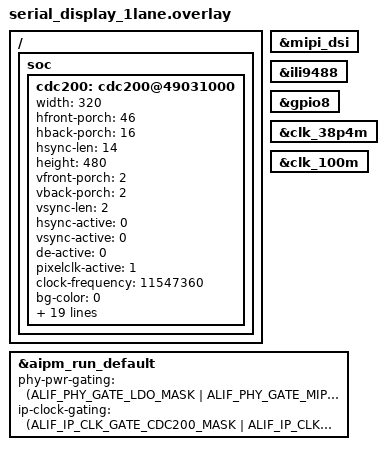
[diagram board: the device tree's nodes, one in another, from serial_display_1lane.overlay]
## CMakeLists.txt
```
# Copyright (C) 2026 Alif Semiconductor - All Rights Reserved.
# Use, distribution and modification of this code is permitted under the
# terms stated in the Alif Semiconductor Software License Agreement
#
# You should have received a copy of the Alif Semiconductor Software
# License Agreement with this file. If not, please write to:
# contact@alifsemi.com, or visit: https://alifsemi.com/license


cmake_minimum_required(VERSION 3.20.0)
find_package(Zephyr REQUIRED HINTS $ENV{ZEPHYR_BASE})
project(disp_pm)

target_sources(app PRIVATE src/main.c src/display_pm_test.c)
target_include_directories(app PRIVATE src)
```

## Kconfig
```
# Copyright (C) 2026 Alif Semiconductor - All Rights Reserved.
# Use, distribution and modification of this code is permitted under the
# terms stated in the Alif Semiconductor Software License Agreement
#
# You should have received a copy of the Alif Semiconductor Software
# License Agreement with this file. If not, please write to:
# contact@alifsemi.com, or visit: https://alifsemi.com/license


mainmenu "Alif Display Power Management Demo"

source "Kconfig.zephyr"
```

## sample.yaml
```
sample:
  name: Alif Display Power Management Demo
  description: >
    Demonstrates Zephyr power management states (PM_STATE_RUNTIME_IDLE,
    PM_STATE_SUSPEND_TO_IDLE, PM_STATE_SUSPEND_TO_RAM, PM_STATE_SOFT_OFF)
    for Alif RTSS cores with Display between PM state transitions.
    PM states exercised are selected via build snippets: display-pm-s2ram-tcm
    (HE TCM retention), display-pm-mram (MRAM boot SOFT_OFF, HE or HP).
common:
  tags:
    - power
    - pm
    - display
    - counter
    - rtc
    - drivers
  filter: SOC_FAMILY_ENSEMBLE
  harness: console
  harness_config:
    type: multi_line
    regex:
      - "DISPLAY PM demo"
      - "POWER STATE SEQUENCE"
tests:
  sample.drivers.display.pm.s2ram_tcm:
    platform_allow:
      - alif_e7_dk_rtss_he
      - alif_e8_dk_rtss_he
      - alif_e1c_dk_rtss_he
      - alif_b1_dk_rtss_he
    integration_platforms:
      - alif_e7_dk_rtss_he
    depends_on:
      - counter
    extra_args:
      - SNIPPET=display-pm-s2ram-tcm
  sample.drivers.display.pm.mram:
    platform_allow:
      - alif_e7_dk_rtss_he
      - alif_e7_dk_rtss_hp
      - alif_e8_dk_rtss_he
      - alif_e8_dk_rtss_hp
      - alif_e1c_dk_rtss_he
      - alif_b1_dk_rtss_he
    integration_platforms:
      - alif_e7_dk_rtss_he
      - alif_e7_dk_rtss_hp
    depends_on:
      - counter
    extra_args:
      - SNIPPET=display-pm-mram
```

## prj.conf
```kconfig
CONFIG_PM=y
CONFIG_PM_DEVICE=y
CONFIG_POWER_DOMAIN=y
CONFIG_IDLE_STACK_SIZE=1024
CONFIG_SYS_CLOCK_TICKS_PER_SEC=1000

CONFIG_COUNTER=y

CONFIG_STDOUT_CONSOLE=y
CONFIG_PRINTK=y
CONFIG_ASSERT=y

CONFIG_LOG=y
CONFIG_LOG_DEFAULT_LEVEL=0
CONFIG_LOG_MODE_DEFERRED=y
CONFIG_LOG_PROCESS_THREAD_SLEEP_MS=5
CONFIG_PM_DEVICE_LOG_LEVEL_WRN=y

# Display
CONFIG_DISPLAY=y
```

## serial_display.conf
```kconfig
# Copyright (C) 2026 Alif Semiconductor - All Rights Reserved.
# Use, distribution and modification of this code is permitted under the
# terms stated in the Alif Semiconductor Software License Agreement
#
# You should have received a copy of the Alif Semiconductor Software
# License Agreement with this file. If not, please write to:
# contact@alifsemi.com, or visit: https://alifsemi.com/license

CONFIG_MIPI_DSI=y
```

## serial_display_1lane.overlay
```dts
/* Copyright (C) Alif Semiconductor - All Rights Reserved.
 * Use, distribution and modification of this code is permitted under the
 * terms stated in the Alif Semiconductor Software License Agreement
 *
 * You should have received a copy of the Alif Semiconductor Software
 * License Agreement with this file. If not, please write to:
 * contact@alifsemi.com, or visit: https://alifsemi.com/license
 *
 */

#include <dt-bindings/misc/alif_aipm_common.h>

/ {
	soc {
		cdc200: cdc200@49031000 {
			width = <320>;
			hfront-porch = <46>;
			hback-porch = <16>;
			hsync-len = <14>;

			height = <480>;
			vfront-porch = <2>;
			vback-porch = <2>;
			vsync-len = <2>;

			hsync-active = <0>;
			vsync-active = <0>;
			de-active = <0>;
			pixelclk-active = <1>;

			clock-frequency = <11547360>;

			bg-color = <0>;
			enable-l1 = <1>;
			pixel-fmt-l1 = "rgb-565";
			def-back-color-l1 = <0>;
			win-x0-l1 = <0>;
			win-y0-l1 = <0>;
			win-x1-l1 = <320>;
			win-y1-l1 = <480>;
			blend-factor1-l1 = <4>;
			blend-factor2-l1 = <5>;
			const-alpha-l1 = <0xff>;
			enable-l2 = <0>;
			pixel-fmt-l2 = "undefined";
			win-x0-l2 = <0>;
			win-y0-l2 = <0>;
			win-x1-l2 = <0>;
			win-y1-l2 = <0>;
			blend-factor1-l2 = <6>;
			blend-factor2-l2 = <7>;
			const-alpha-l2 = <0xff>;
		};
	};
};

&mipi_dsi {
	status = "okay";
};

&ili9488 {
	status = "okay";
};

&gpio8 {
	status = "okay";
};

/* enable HFOSC clock clk_38p4m. */
&clk_38p4m {
	status = "okay";
};

/* enable CFG clock clk_100m. */
&clk_100m {
	status = "okay";
};

&aipm_run_default {
	phy-pwr-gating = <(ALIF_PHY_GATE_LDO_MASK |
			ALIF_PHY_GATE_MIPI_TX_DPHY_MASK |
			ALIF_PHY_GATE_MIPI_RX_DPHY_MASK |
			ALIF_PHY_GATE_MIPI_PLL_DPHY_MASK)>;
	ip-clock-gating = <(ALIF_IP_CLK_GATE_CDC200_MASK |
			ALIF_IP_CLK_GATE_MIPI_DSI_MASK |
			ALIF_IP_CLK_GATE_GPU_MASK)>;
};
```

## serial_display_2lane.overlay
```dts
/* Copyright (C) 2026 Alif Semiconductor - All Rights Reserved.
 * Use, distribution and modification of this code is permitted under the
 * terms stated in the Alif Semiconductor Software License Agreement
 *
 * You should have received a copy of the Alif Semiconductor Software
 * License Agreement with this file. If not, please write to:
 * contact@alifsemi.com, or visit: https://alifsemi.com/license
 *
 */

/ {
	soc {
		cdc200: cdc200@49031000 {
			width = <480>;
			height = <800>;
			hfront-porch = <5>;
			hback-porch = <5>;
			hsync-len = <4>;
			vfront-porch = <10>;
			vback-porch = <10>;
			vsync-len = <2>;
			clock-frequency = <24364080>;
			hsync-active = <0>;
			vsync-active = <0>;
			de-active = <1>;
			pixelclk-active = <0>;
			bg-color = <0>;
			enable-l1 = <1>;
			pixel-fmt-l1 = "rgb-888";
			def-back-color-l1 = <0>;
			win-x0-l1 = <0>;
			win-y0-l1 = <0>;
			win-x1-l1 = <480>;
			win-y1-l1 = <800>;
			blend-factor1-l1 = <4>;
			blend-factor2-l1 = <5>;
			const-alpha-l1 = <0xff>;
			enable-l2 = <0>;
			pixel-fmt-l2 = "undefined";
			win-x0-l2 = <0>;
			win-y0-l2 = <0>;
			win-x1-l2 = <0>;
			win-y1-l2 = <0>;
			blend-factor1-l2 = <6>;
			blend-factor2-l2 = <7>;
			const-alpha-l2 = <0xff>;
		};
	};
};

&mipi_dsi {
	status = "okay";
};

/* enable HFOSC clock clk_38p4m. */
&clk_38p4m {
	status = "okay";
};

/* enable CFG clock clk_100m. */
&clk_100m {
	status = "okay";
};

&aipm_run_default {
	phy-pwr-gating = <(ALIF_PHY_GATE_LDO_MASK |
			ALIF_PHY_GATE_MIPI_TX_DPHY_MASK |
			ALIF_PHY_GATE_MIPI_RX_DPHY_MASK |
			ALIF_PHY_GATE_MIPI_PLL_DPHY_MASK)>;
	ip-clock-gating = <(ALIF_IP_CLK_GATE_CDC200_MASK |
			ALIF_IP_CLK_GATE_MIPI_DSI_MASK |
			ALIF_IP_CLK_GATE_GPU_MASK)>;
};
```

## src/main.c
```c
/* Copyright (C) 2026 Alif Semiconductor - All Rights Reserved.
 * Use, distribution and modification of this code is permitted under the
 * terms stated in the Alif Semiconductor Software License Agreement
 *
 * You should have received a copy of the Alif Semiconductor Software
 * License Agreement with this file. If not, please write to:
 * contact@alifsemi.com, or visit: https://alifsemi.com/license
 *
 */

#include "aipm.h"
#include <stdio.h>
#include <zephyr/kernel.h>
#include <zephyr/device.h>
#include <zephyr/init.h>
#include <zephyr/pm/pm.h>
#include <zephyr/pm/policy.h>
#if defined(CONFIG_POWEROFF)
#include <zephyr/sys/poweroff.h>
#endif
#include <zephyr/drivers/counter.h>
#include <se_service.h>
#include <soc_common.h>
#include <zephyr/sys/util.h>
#include <zephyr/logging/log.h>
#include "display_pm_test.h"
#include <zephyr/drivers/clock_control.h>
#include <zephyr/dt-bindings/clock/alif_ensemble_clocks.h>
#include <zephyr/drivers/gpio.h>

LOG_MODULE_REGISTER(disp_pm, LOG_LEVEL_DBG);

/* Set to 1 to dump full NVIC ISPR state on wakeup */
#define APP_PM_WAKEUP_DEBUG 0

#if DT_NODE_HAS_COMPAT_STATUS(DT_NODELABEL(rtc0), snps_dw_apb_rtc, okay)
	#define WAKEUP_SOURCE DT_NODELABEL(rtc0)
#elif DT_NODE_HAS_COMPAT_STATUS(DT_NODELABEL(timer0), snps_dw_timers, okay)
	#define WAKEUP_SOURCE DT_NODELABEL(timer0)
#else
#error "Wakeup Device not enabled in the dts"
#endif

/*
 * Sleep duration constants for each PM state.
 *
 * Upper bound: at 400 MHz, ticks to cycles calculation in PM driver
 * overflows uint32 max for values > 10.7s (2^32 / 400). All deep-sleep
 * durations and overlay min-residency-us values must stay below this ceiling.
 */
/* Sleep duration for PM_STATE_RUNTIME_IDLE */
#define RUNTIME_IDLE_SLEEP_USEC (10 * 1000 * 1000)
/* Sleep duration for PM_STATE_SUSPEND_TO_IDLE */
#define SUSPEND_IDLE_SLEEP_USEC (10 * 1000)
/* Sleep duration for PM_STATE_SUSPEND_TO_RAM substate 0 (STANDBY) */
#define S2RAM_STANDBY_SLEEP_USEC (6 * 1000 * 1000)
/* Sleep duration for PM_STATE_SUSPEND_TO_RAM substate 1 (STOP) */
#define S2RAM_STOP_SLEEP_USEC (9 * 1000 * 1000)
/* Sleep duration for PM_STATE_SOFT_OFF */
#define SOFT_OFF_SLEEP_USEC (10 * 1000 * 1000)

/*
 * MRAM base address - used to determine boot location
 * TCM boot: VTOR = 0x0
 * MRAM boot: VTOR >= 0x80000000
 */
#define MRAM_BASE_ADDRESS 0x80000000

/*
 * Helper macro to check if booting from MRAM
 */
#define IS_BOOTING_FROM_MRAM() (SCB->VTOR >= MRAM_BASE_ADDRESS)

/*
 * True when the DTS chosen zephyr,sram points at sram0. The snippet overlay
 * is responsible for ensuring SRAM0 has retention support on the target board.
 */
#if DT_NODE_EXISTS(DT_NODELABEL(sram0))
#define IS_SRAM0_CONFIGURED_AS_RAM() \
	DT_SAME_NODE(DT_CHOSEN(zephyr_sram), DT_NODELABEL(sram0))
#else
#define IS_SRAM0_CONFIGURED_AS_RAM() 0
#endif

/*
 * S2RAM_SUPPORTED — retention-capable sleep is possible when:
 *   - SRAM0 is the configured data RAM (HE or HP, E8 only), OR
 *   - HE core booting from TCM (TCM has hardware retention)
 *
 * SOFT_OFF_SUPPORTED — mutually exclusive with S2RAM: used when no
 * retained RAM is available (HP-TCM, HE-MRAM boot without SRAM0).
 */
#define S2RAM_SUPPORTED \
	(IS_SRAM0_CONFIGURED_AS_RAM() || \
	 (IS_ENABLED(CONFIG_RTSS_HE) && !IS_BOOTING_FROM_MRAM()))

#define SOFT_OFF_SUPPORTED (!S2RAM_SUPPORTED)

/* Validate ordering of deep-sleep durations at compile time */
BUILD_ASSERT((S2RAM_STOP_SLEEP_USEC > S2RAM_STANDBY_SLEEP_USEC),
	"STOP sleep duration should be greater than STANDBY sleep duration");
BUILD_ASSERT((SOFT_OFF_SLEEP_USEC > S2RAM_STOP_SLEEP_USEC),
	"SOFT_OFF sleep duration should be greater than STOP sleep duration");

/**
 * Helper function to lock/unlock deeper power states.
 * @param lock true → lock all deep states (allow RUNTIME_IDLE only)
 *             false → unlock the applicable state; keep the other locked
 */
static void app_pm_lock_deeper_states(bool lock)
{
	if (lock) {
		pm_policy_state_lock_get(PM_STATE_SUSPEND_TO_RAM, PM_ALL_SUBSTATES);
		pm_policy_state_lock_get(PM_STATE_SOFT_OFF,       PM_ALL_SUBSTATES);
	} else {
		pm_policy_state_lock_put(PM_STATE_SOFT_OFF,       PM_ALL_SUBSTATES);
		pm_policy_state_lock_put(PM_STATE_SUSPEND_TO_RAM, PM_ALL_SUBSTATES);
	}
}

/*
 * Lock every PM sleep state deeper than RUNTIME_IDLE. Intended for use around
 * peripheral transfers (see spi_loopback_run()) and around any sleep call the
 * app makes where an accidental upgrade to a deeper state must be prevented.
 */
static void app_pm_lock_sleep_states(bool lock)
{
	if (lock) {
		pm_policy_state_lock_get(PM_STATE_SUSPEND_TO_IDLE, PM_ALL_SUBSTATES);
		pm_policy_state_lock_get(PM_STATE_SUSPEND_TO_RAM,  PM_ALL_SUBSTATES);
		pm_policy_state_lock_get(PM_STATE_SOFT_OFF,        PM_ALL_SUBSTATES);
	} else {
		pm_policy_state_lock_put(PM_STATE_SOFT_OFF,        PM_ALL_SUBSTATES);
		pm_policy_state_lock_put(PM_STATE_SUSPEND_TO_RAM,  PM_ALL_SUBSTATES);
		pm_policy_state_lock_put(PM_STATE_SUSPEND_TO_IDLE, PM_ALL_SUBSTATES);
	}
}

#if !defined(CONFIG_CORTEX_M_SYSTICK_LPM_TIMER_COUNTER)
static volatile uint32_t alarm_cb_status;
static void alarm_callback_fn(const struct device *wakeup_dev,
				uint8_t chan_id, uint32_t ticks,
				void *user_data)
{
	LOG_DBG("%s: Alarm triggered", wakeup_dev->name);
	alarm_cb_status = 1;
}
#endif

static int app_enter_normal_sleep(uint32_t sleep_usec)
{
	int ret;

	ret = display_pm_thread_suspend();
	if (ret) {
		LOG_ERR("Failed to suspend display thread: %d", ret);
		return ret;
	}
	LOG_INF("Display streaming is Suspended: for normal sleep");

#if defined(CONFIG_CORTEX_M_SYSTICK_LPM_TIMER_COUNTER)
	k_sleep(K_USEC(sleep_usec));
#else
	const struct device *const wakeup_dev = DEVICE_DT_GET(WAKEUP_SOURCE);
	struct counter_alarm_cfg alarm_cfg;

	alarm_cfg.flags = 0;
	alarm_cfg.ticks = counter_us_to_ticks(wakeup_dev, sleep_usec);
	alarm_cfg.callback = alarm_callback_fn;
	alarm_cfg.user_data = &alarm_cfg;

	ret = counter_set_channel_alarm(wakeup_dev, 0, &alarm_cfg);
	if (ret) {
		LOG_ERR("Could not set the alarm");
		display_pm_thread_resume();
		return ret;
	}
	LOG_DBG("Set alarm for %u microseconds", sleep_usec);

	k_sleep(K_USEC(sleep_usec));

	if (!alarm_cb_status) {
		display_pm_thread_resume();
		return -1;
	}
	alarm_cb_status = 0;

#endif
	return 0;
}

static int app_enter_deep_sleep(uint32_t sleep_usec)
{
	int ret;

	ret = display_pm_thread_suspend();
	if (ret) {
		LOG_ERR("Failed to suspend display thread: %d", ret);
		return ret;
	}
	LOG_INF("Display streaming is Suspended: for Deep Sleep");

#if defined(CONFIG_CORTEX_M_SYSTICK_LPM_TIMER_COUNTER)
	/**
	 * Set a delay more than the min-residency-us configured so that
	 * the sub-system will go to OFF state.
	 */
	k_sleep(K_USEC(sleep_usec));
#else
	const struct device *const wakeup_dev = DEVICE_DT_GET(WAKEUP_SOURCE);
	struct counter_alarm_cfg alarm_cfg = {0};
	/*
	 * Set the alarm and delay so that idle thread can run
	 */
	alarm_cfg.ticks = counter_us_to_ticks(wakeup_dev, sleep_usec);
	alarm_cfg.callback = alarm_callback_fn;
	ret = counter_set_channel_alarm(wakeup_dev, 0, &alarm_cfg);
	if (ret) {
		LOG_ERR("Failed to set the alarm (err %d)", ret);
		display_pm_thread_resume();
		return ret;
	}

	LOG_DBG("Set alarm for %u microseconds", sleep_usec);
	/*
	 * Wait for the alarm to trigger. The idle thread will
	 * take care of entering the deep sleep state via PM framework.
	 */
	k_sleep(K_USEC(sleep_usec));
#endif

	ret = display_pm_thread_resume();
	if (ret) {
		LOG_ERR("Failed to resume display thread: %d", ret);
		return ret;
	}
	LOG_INF("Display stream is Resumed: for Deep Sleep");

	return 0;
}

/* PM state name lookup for notifier logging */
static const char * const pm_state_names[] = {
	[PM_STATE_ACTIVE]          = "ACTIVE",
	[PM_STATE_RUNTIME_IDLE]    = "RUNTIME_IDLE",
	[PM_STATE_SUSPEND_TO_IDLE] = "SUSPEND_TO_IDLE",
	[PM_STATE_STANDBY]         = "STANDBY",
	[PM_STATE_SUSPEND_TO_RAM]  = "SUSPEND_TO_RAM",
	[PM_STATE_SUSPEND_TO_DISK] = "SUSPEND_TO_DISK",
	[PM_STATE_SOFT_OFF]        = "SOFT_OFF",
};

#define PM_STATE_STR(s) \
	((s) < ARRAY_SIZE(pm_state_names) ? pm_state_names[(s)] : "UNKNOWN")

static void pm_notify_entry(enum pm_state state)
{
	const struct pm_state_info *info = pm_state_next_get(0);

	LOG_INF("PM enter: %s (substate %u)", PM_STATE_STR(state), info->substate_id);
}

/*
 * With CONFIG_LOG_MODE_DEFERRED, LOG_INF here only writes to the ring buffer
 * — no UART access — so this is safe even before devices are resumed.
 */
static void pm_notify_pre_resume(enum pm_state state)
{
	const struct pm_state_info *info = pm_state_next_get(0);
	uint32_t active_exc = SCB->ICSR & SCB_ICSR_VECTACTIVE_Msk;

	if (active_exc >= 16U) {
		LOG_INF("PM wakeup: %s (substate %u) IRQ %u",
			PM_STATE_STR(state), info->substate_id, active_exc - 16U);
	} else if (active_exc != 0U) {
		LOG_INF("PM wakeup: %s (substate %u) exception %u",
			PM_STATE_STR(state), info->substate_id, active_exc);
	} else {
		LOG_INF("PM wakeup: %s (substate %u)",
			PM_STATE_STR(state), info->substate_id);
	}
#if APP_PM_WAKEUP_DEBUG
	for (int i = 0; i < 16; i++) {
		if (NVIC->ISPR[i]) {
			LOG_INF("PM wakeup: NVIC ISPR[%d] = 0x%08x", i, NVIC->ISPR[i]);
		}
	}
#endif

	if (info->substate_id == 1) {
#if (defined(CONFIG_ENSEMBLE_GEN2) && defined(CONFIG_MIPI_DSI))
		const struct gpio_dt_spec cam_disp_mux_gpio =
			GPIO_DT_SPEC_GET(DT_NODELABEL(mipi_dsi), cam_disp_mux_gpios);
		gpio_pin_configure_dt(&cam_disp_mux_gpio, GPIO_OUTPUT_ACTIVE);
#endif
	}
}

static void pm_notify_exit(enum pm_state state)
{
	const struct pm_state_info *info = pm_state_next_get(0);

	LOG_INF("PM exit:  %s (substate %u)", PM_STATE_STR(state), info->substate_id);
}

static struct pm_notifier app_pm_notifier = {
	.state_entry       = pm_notify_entry,
	.pre_device_resume = pm_notify_pre_resume,
	.state_exit        = pm_notify_exit,
};

int main(void)
{
	const struct device *const cons = DEVICE_DT_GET(DT_CHOSEN(zephyr_console));
	const struct device *const wakeup_dev = DEVICE_DT_GET(WAKEUP_SOURCE);
	int ret;

	__ASSERT(device_is_ready(cons), "%s: device not ready", cons->name);
	__ASSERT(device_is_ready(wakeup_dev), "%s: device not ready", wakeup_dev->name);

	pm_notifier_register(&app_pm_notifier);

	if (S2RAM_SUPPORTED) {
		LOG_INF("%s (S2RAM): Display PM demo "
			"(RUNTIME_IDLE, SUSPEND_TO_IDLE, S2RAM STANDBY, S2RAM STOP)",
			CONFIG_BOARD);
	} else {
		LOG_INF("%s (SOFT_OFF): Display PM demo "
			"(RUNTIME_IDLE, SUSPEND_TO_IDLE, SOFT_OFF)",
			CONFIG_BOARD);
	}

	display_pm_thread_init();
	display_pm_thread_start();

	ret = counter_start(wakeup_dev);
	__ASSERT(!ret || ret == -EALREADY, "Failed to start counter (err %d)", ret);

	LOG_INF("POWER STATE SEQUENCE:");
	/* HE core: sequence depends on boot location */
	LOG_INF("  1. PM_STATE_RUNTIME_IDLE");
	LOG_INF("  2. PM_STATE_SUSPEND_TO_IDLE");
	if (S2RAM_SUPPORTED) {
		/* TCM boot: S2RAM works (TCM retention) */
		LOG_INF("  3. PM_STATE_SUSPEND_TO_RAM (substate 0: STANDBY)");
		LOG_INF("  4. PM_STATE_SUSPEND_TO_RAM (substate 1: STOP)");
	} else {
		/* MRAM boot: Enable Only SOFT_OFF */
		LOG_INF("  3. PM_STATE_SOFT_OFF");
	}

	LOG_INF("Enter RUNTIME_IDLE sleep for (%d microseconds)", RUNTIME_IDLE_SLEEP_USEC);
	app_pm_lock_sleep_states(true);
	ret = app_enter_normal_sleep(RUNTIME_IDLE_SLEEP_USEC);
	app_pm_lock_sleep_states(false);
	__ASSERT(ret == 0, "Could not enter RUNTIME_IDLE sleep (err %d)", ret);

	LOG_INF("Exited from RUNTIME_IDLE sleep");

	display_pm_thread_resume();
	ret = display_pm_wait_streaming_done();
	__ASSERT(ret == 0, "Display stream did not complete successfully (err %d)", ret);
	LOG_INF("Display streaming cycle OK (RUNTIME_IDLE)");

#if defined(CONFIG_CORTEX_M_SYSTICK_LPM_TIMER_COUNTER)
	LOG_INF("Request SUSPEND_TO_IDLE for %d us", SUSPEND_IDLE_SLEEP_USEC);
	app_pm_lock_deeper_states(true);
	k_sleep(K_USEC(SUSPEND_IDLE_SLEEP_USEC));
	app_pm_lock_deeper_states(false);
	LOG_INF("Exited from SUSPEND_TO_IDLE sleep");
#else
	/* Lock SUSPEND_TO_IDLE when LPM timer support is not configured */
	pm_policy_state_lock_get(PM_STATE_SUSPEND_TO_IDLE, PM_ALL_SUBSTATES);
	LOG_INF("PM_STATE_SUSPEND_TO_IDLE (skipped - LPM timer not enabled)");
#endif

	if (S2RAM_SUPPORTED) {
		LOG_INF("Request S2RAM STANDBY for %d us", S2RAM_STANDBY_SLEEP_USEC);
		ret = app_enter_deep_sleep(S2RAM_STANDBY_SLEEP_USEC);
		__ASSERT(ret == 0, "Could not enter PM_STATE_SUSPEND_TO_RAM (err %d)", ret);

		LOG_INF("=== Resumed from PM_STATE_SUSPEND_TO_RAM (substate 0: STANDBY) ===");

		display_pm_wait_streaming_done();
		LOG_INF("Display streaming cycle OK (RUNTIME_IDLE)");

		/* Verify main thread is running properly */
		for (int i = 0; i < 3; i++) {
			LOG_INF("Main thread running - iteration %d - tick: %llu",
				i, k_uptime_ticks());
			k_sleep(K_SECONDS(2));
		}

		LOG_INF("Request S2RAM STOP for %d us", S2RAM_STOP_SLEEP_USEC);
		ret = app_enter_deep_sleep(S2RAM_STOP_SLEEP_USEC);
		__ASSERT(ret == 0, "Could not enter PM_STATE_SUSPEND_TO_RAM (err %d)", ret);

		LOG_INF("=== Resumed from PM_STATE_SUSPEND_TO_RAM (substate 1: STOP) ===");

		display_pm_wait_streaming_done();
		LOG_INF("Display streaming cycle OK (STOP)");

		/* Verify main thread is running properly */
		for (int i = 0; i < 3; i++) {
			LOG_INF("Main thread running - iteration %d - tick: %llu",
				i, k_uptime_ticks());
			k_sleep(K_SECONDS(2));
		}
	}

	/* HE core: only SOFT_OFF when booting from MRAM */
	if (SOFT_OFF_SUPPORTED) {
		LOG_INF("Request SOFT_OFF for %d us (no retention - system resets on wakeup)",
			SOFT_OFF_SLEEP_USEC);
		ret = app_enter_deep_sleep(SOFT_OFF_SLEEP_USEC);
		__ASSERT(ret == 0, "Could not enter PM_STATE_SOFT_OFF (err %d)", ret);

		/* Should never reach here - SOFT_OFF causes full reset on wakeup */
		LOG_ERR("ERROR: Resumed after PM_STATE_SOFT_OFF - this should not happen!");
		__ASSERT(false, "PM_STATE_SOFT_OFF should have caused a reset");
	}

	LOG_INF("=== DISPLAY PM SEQUENCE COMPLETED ===");

	display_pm_thread_stop();
	LOG_INF("Display Streaming is Stopped (PM sequence done)");

	app_pm_lock_deeper_states(true);
	/* Demo complete — prevent SUSPEND_TO_IDLE so the idle spin stays in RUNTIME_IDLE */
	pm_policy_state_lock_get(PM_STATE_SUSPEND_TO_IDLE, PM_ALL_SUBSTATES);

	while (true) {
		/* spin here */
		k_sleep(K_SECONDS(1));
	}

	return 0;
}
```

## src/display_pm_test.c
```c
/* Copyright (C) 2026 Alif Semiconductor - All Rights Reserved.
 * Use, distribution and modification of this code is permitted under the
 * terms stated in the Alif Semiconductor Software License Agreement
 *
 * You should have received a copy of the Alif Semiconductor Software
 * License Agreement with this file. If not, please write to:
 * contact@alifsemi.com, or visit: https://alifsemi.com/license
 *
 */

#include <zephyr/kernel.h>
#include <zephyr/device.h>
#include <zephyr/devicetree.h>
#include <string.h>
#include <zephyr/drivers/gpio.h>
#include <zephyr/drivers/display.h>
#include <zephyr/drivers/display/cdc200.h>
#include <soc_common.h>
#include <se_service.h>
#include <zephyr/pm/device.h>
#include <zephyr/pm/policy.h>
#include <zephyr/logging/log.h>
#ifdef CONFIG_MIPI_DSI
#include <zephyr/drivers/mipi_dsi/dsi_dw.h>
#endif /* CONFIG_MIPI_DSI */
#include <zephyr/cache.h>
#include "alif_logo.h"

#include "display_pm_test.h"

LOG_MODULE_DECLARE(disp_pm, LOG_LEVEL_DBG);

/* size of stack area used by each thread */
#define STACKSIZE 4096

/* Thread Priority */
#define DISPLAY_PRIORITY 7

#define RED_ARGB8888	0x00ff0000
#define GREEN_ARGB8888	0x0000ff00
#define BLUE_ARGB8888	0x000000ff
#define RED_RGB888	    0x00ff0000
#define GREEN_RGB888	0x0000ff00
#define BLUE_RGB888	    0x000000ff
#define RED_RGB565	    0xf800
#define GREEN_RGB565	0x07e0
#define BLUE_RGB565	    0x001f

#define CDC200_PIXEL_SIZE_ARGB8888	4
#define CDC200_PIXEL_SIZE_RGB888	3
#define CDC200_PIXEL_SIZE_RGB565	2

K_THREAD_STACK_DEFINE(DisplayT_stack, STACKSIZE);
static struct k_thread thread_display;

/* Semaphore for PM suspend/resume synchronization */
K_SEM_DEFINE(display_pm_resume_sem, 0, 1);

/* Semaphore to signal that display thread has suspended */
K_SEM_DEFINE(display_pm_suspended_sem, 0, 1);

/* Semaphore to signal that a streaming has completed */
K_SEM_DEFINE(display_streaming_done_sem, 0, 1);

/* Thread control flags */
static volatile uint8_t THREAD_TO_BE_SUSPEND;
static volatile uint8_t THREAD_SUSPENDED;
static volatile uint8_t THREAD_TO_BE_STOPPED;

/* display device */
static const struct device *display_dev;

#if defined(CONFIG_MIPI_DSI)
/* Panel device for PM actions */
static const struct device *panel_dev;

/* DSI device for PM actions */
static const struct device *dsi_dev;

static const struct device *dphy_dev;
#endif /* defined(CONFIG_MIPI_DSI) */

/* Tracks whether streaming was active when the PM suspend was requested,
 * so we only auto-restart stream on resume if it was streaming before.
 */
static bool was_streaming;

static bool streaming_active;

enum corner {
	TOP_LEFT,
	TOP_RIGHT,
	BOTTOM_RIGHT,
	BOTTOM_LEFT
};

typedef void (*fill_buffer)(enum corner corner, uint8_t grey, uint8_t *buf,
			    size_t buf_size);

struct display_capabilities panel_caps;

struct display_buffer_descriptor buf_desc;

struct cdc200_display_caps capabilities;

struct cdc200_fb_desc fb_l2 = { 0 };

fill_buffer fill_buffer_fnc;

size_t pixel_size;
size_t buf_size;
size_t rect_w = 2;
size_t rect_h = 1;
uint8_t *buf;
size_t scale;
size_t x;
size_t y;

#if (!defined(CONFIG_MIPI_DSI) || \
	!DT_NODE_HAS_PROP(DT_ALIAS(mipi_dsi), dpi_video_pattern_gen))
static void fill_buffer_argb8888(enum corner corner, uint8_t grey, uint8_t *buf,
				 size_t buf_size)
{
	uint32_t color = 0;

	switch (corner) {
	case TOP_LEFT:
		color = RED_ARGB8888;
		break;
	case TOP_RIGHT:
		color = GREEN_ARGB8888;
		break;
	case BOTTOM_RIGHT:
		color = BLUE_ARGB8888;
		break;
	case BOTTOM_LEFT:
		color = grey << 16 | grey << 8 | grey;
		break;
	}

	for (size_t idx = 0; idx < buf_size; idx += 4) {
		*((uint32_t *)(buf + idx)) = color;
	}
}

static void fill_buffer_rgb888(enum corner corner, uint8_t grey, uint8_t *buf,
			       size_t buf_size)
{
	uint32_t color = 0;

	switch (corner) {
	case TOP_LEFT:
		color = RED_RGB888;
		break;
	case TOP_RIGHT:
		color = GREEN_RGB888;
		break;
	case BOTTOM_RIGHT:
		color = BLUE_RGB888;
		break;
	case BOTTOM_LEFT:
		color = grey << 16 | grey << 8 | grey;
		break;
	}

	for (size_t idx = 0; idx < buf_size; idx += 3) {
		*(buf + idx + 2) = (color >> 16) & 0xff;
		*(buf + idx + 1) = (color >> 8) & 0xff;
		*(buf + idx + 0) = (color >> 0) & 0xff;
	}
}

static uint16_t get_rgb565_color(enum corner corner, uint8_t grey)
{
	uint16_t color = 0;

	switch (corner) {
	case TOP_LEFT:
		color = RED_RGB565;
		break;
	case TOP_RIGHT:
		color = GREEN_RGB565;
		break;
	case BOTTOM_RIGHT:
		color = BLUE_RGB565;
		break;
	case BOTTOM_LEFT:
		color = (grey & 0x1f) << 11 |
			(grey & 0x3f) << 5 | (grey & 0x1F);
		break;
	}
	return color;
}

static void fill_buffer_rgb565(enum corner corner, uint8_t grey, uint8_t *buf,
			       size_t buf_size)
{
	uint16_t color = get_rgb565_color(corner, grey);

	for (size_t idx = 0; idx < buf_size; idx += 2) {
		*(buf + idx + 1) = (color >> 8) & 0xFFu;
		*(buf + idx + 0) = (color >> 0) & 0xFFu;
	}
}

int get_pixel_size(enum display_pixel_format fmt)
{
	if (fmt == PIXEL_FORMAT_RGB_888)
		return CDC200_PIXEL_SIZE_RGB888;
	else if (fmt == PIXEL_FORMAT_ARGB_8888)
		return CDC200_PIXEL_SIZE_ARGB8888;
	else if (fmt == PIXEL_FORMAT_RGB_565)
		return CDC200_PIXEL_SIZE_RGB565;
	else
		return 0;
}
#endif /* (!defined(CONFIG_MIPI_DSI) || \
	* !DT_NODE_HAS_PROP(DT_ALIAS(mipi_dsi), dpi_video_pattern_gen))
	*/

/*
 * Initialize display (called once at startup)
 */
static int display_init(void)
{
#if defined(CONFIG_MIPI_DSI)
	int ret;

	panel_dev = DEVICE_DT_GET(DT_ALIAS(panel));
	if (!device_is_ready(panel_dev)) {
		LOG_ERR("Panel device not ready");
		return -1;
	}

	dsi_dev = DEVICE_DT_GET(DT_ALIAS(mipi_dsi));
	if (!device_is_ready(dsi_dev)) {
		LOG_ERR("DSI device not ready");
		return -1;
	}

	dphy_dev = DEVICE_DT_GET_ONE(snps_designware_dphy);
	if (!device_is_ready(dphy_dev)) {
		LOG_ERR("DPHY device not ready");
		return -1;
	}

	ret = display_set_orientation(panel_dev, DISPLAY_ORIENTATION_ROTATED_180);
	if (ret == -ENOTSUP)
		LOG_DBG("Un-supported Display Rotation.");

	/* DISPOFF must go out while the host is still in command mode. */
	display_blanking_on(panel_dev);

	ret = dsi_dw_set_mode(dsi_dev, DSI_DW_VIDEO_MODE);
	if (ret) {
		LOG_ERR("DSI Host controller set to video mode.");
		return -1;
	}

	display_get_capabilities(panel_dev, &panel_caps);
#endif /* defined(CONFIG_MIPI_DSI) */

	display_dev = DEVICE_DT_GET(DT_CHOSEN(zephyr_display));
	if (!device_is_ready(display_dev)) {
		LOG_ERR("CDC200 device not ready");
		return -1;
	}

	LOG_INF("Enabling CDC200 Device.");
	cdc200_set_enable(display_dev, true);
	display_blanking_on(display_dev);
	cdc200_get_capabilities(display_dev, &capabilities);

	LOG_INF("Display init: %s, panel res (%d, %d), fmt %d", display_dev->name,
		capabilities.x_panel_resolution, capabilities.y_panel_resolution,
		capabilities.supported_pixel_formats);

	for (int i = 0; i <= 1; i++) {
		LOG_DBG("Layer %d: en=%d res=(%d,%d) fmt=%d", i + 1,
			capabilities.layer[i].layer_en,
			capabilities.layer[i].x_resolution,
			capabilities.layer[i].y_resolution,
			capabilities.layer[i].current_pixel_format);
	}

	scale = (capabilities.layer[0].x_resolution / 8);
	rect_w *= scale;
	rect_h *= scale;
	buf_size = rect_w * rect_h;

	if (buf_size < (capabilities.layer[0].x_resolution)) {
		buf_size = capabilities.layer[0].x_resolution;
	}

	pixel_size =
		MAX(get_pixel_size(capabilities.layer[0].current_pixel_format),
		get_pixel_size(capabilities.layer[1].current_pixel_format));
	buf_size *= pixel_size;

	switch (capabilities.layer[0].current_pixel_format) {
	case PIXEL_FORMAT_ARGB_8888:
		fill_buffer_fnc = fill_buffer_argb8888;
		break;
	case PIXEL_FORMAT_RGB_888:
		fill_buffer_fnc = fill_buffer_rgb888;
		break;
	case PIXEL_FORMAT_RGB_565:
		fill_buffer_fnc = fill_buffer_rgb565;
		break;
	default:
		LOG_ERR("Unsupported pixel format. Aborting sample.");
		return -1;
	}

	buf = k_malloc(buf_size);
	if (buf == NULL) {
		LOG_ERR("Could not allocate memory."
			"Aborting sample. Required Heap Size - %d", buf_size);
		return -1;
	}

	return 0;
}

/*
 * Display streaming thread function
 */
static void display_streaming_thread(void *p1, void *p2, void *p3)
{
	int ret;
	bool pm_locks_held = false;

	ARG_UNUSED(p1);
	ARG_UNUSED(p2);
	ARG_UNUSED(p3);

	if (!was_streaming) {
		LOG_INF("skip starting a new stream cycle this round");
		THREAD_TO_BE_SUSPEND = 1;
	}

	/* Initialize display */
	ret = display_init();
	if (ret) {
		LOG_ERR("Display initialization failed: %d", ret);
		return;
	}

	while (1) {
		/* Check if thread should be stopped (PM sequence done) */
		if (THREAD_TO_BE_STOPPED) {
			LOG_INF("Display: thread stopping (PM sequence completed)");
			return;
		}

		if (!streaming_active) {
			/*
			 * Check if thread should be suspended (PM cycle).
			 * Only suspend when streaming is not active.
			 */
			if (THREAD_TO_BE_SUSPEND) {
				THREAD_SUSPENDED = 1;
				LOG_INF("Display: putting thread into wait for PM resume");

				/* Signal that we are now suspended */
				k_sem_give(&display_pm_suspended_sem);

				/* Block on semaphore - does not wake system like k_msleep */
				k_sem_take(&display_pm_resume_sem, K_FOREVER);

				/* Check if we were woken to stop rather than resume */
				if (THREAD_TO_BE_STOPPED) {
					LOG_INF("Display: thread stopping (suspend)");
					return;
				}

				LOG_INF("Display: Woken up by PM resume");
				THREAD_SUSPENDED = 0;

				/*
				 * Lock deeper PM states during display resume
				 * sequence to prevent S2RAM from trashing
				 * hardware state mid-reinit.
				 */
				pm_policy_state_lock_get(PM_STATE_SUSPEND_TO_RAM,
							PM_ALL_SUBSTATES);
				pm_policy_state_lock_get(PM_STATE_SOFT_OFF,
							PM_ALL_SUBSTATES);
				pm_locks_held = true;

				/* The PM framework already ran SUSPEND/RESUME on
				 * every PM device in dependency order, so the
				 * DPHY, CSI2, CPI and sensor are usable by the
				 * time we get here. Only the pipeline format has
				 * to be re-applied to start a new capture cycle.
				 */

#if defined(CONFIG_MIPI_DSI)
				/*
				 * blanking_off() waits for panel resume, which
				 * re-attaches the DSI host in command mode.
				 * Switch to video only after DISPON has been sent.
				 */
				display_set_orientation(panel_dev, DISPLAY_ORIENTATION_ROTATED_180);
				display_blanking_off(panel_dev);
				dsi_dw_set_mode(dsi_dev, DSI_DW_VIDEO_MODE);
#endif /* defined(CONFIG_MIPI_DSI) */

				cdc200_set_enable(display_dev, true);
			}

			streaming_active = true;
		}

		if (capabilities.layer[1].layer_en) {
			cdc200_get_framebuffer(display_dev, 1, &fb_l2);
			memset((uint8_t *) fb_l2.fb_addr, 0, fb_l2.fb_size);
			memcpy((uint8_t *) fb_l2.fb_addr, logo, sizeof(logo));
			sys_cache_data_flush_range((void *)fb_l2.fb_addr, sizeof(logo));
		}

		if (capabilities.layer[0].layer_en) {
			cdc200_get_framebuffer(display_dev, 0, &fb_l2);
			LOG_INF("FB0 - 0x%08x, size - %d",
				(uint32_t)fb_l2.fb_addr, fb_l2.fb_size);
			(void)memset(buf, 0xFFu, buf_size);

			buf_desc.buf_size = buf_size;
			buf_desc.pitch = capabilities.layer[0].x_resolution;
			buf_desc.width = capabilities.layer[0].x_resolution;
			buf_desc.height = 1;

			int row_errs = 0;

			for (int idx = 0; idx < capabilities.layer[0].y_resolution; idx += 1) {
				ret = cdc200_display_write(display_dev, 0, 0, idx, &buf_desc, buf);
				if (ret) {
					row_errs++;
				}
			}
			if (row_errs) {
				LOG_ERR("cdc200_display_write failed on %d row(s)", row_errs);
			}

			buf_desc.pitch = rect_w;
			buf_desc.width = rect_w;
			buf_desc.height = rect_h;

			fill_buffer_fnc(TOP_LEFT, 0, buf, buf_size);
			x = 0;
			y = 0;

			ret = cdc200_display_write(display_dev, 0, x, y, &buf_desc, buf);
			if (ret) {
				LOG_ERR("cdc200_display_write failed (TOP_LEFT)");
			}

			fill_buffer_fnc(TOP_RIGHT, 0, buf, buf_size);
			x = capabilities.layer[0].x_resolution - rect_w;
			y = 0;

			ret = cdc200_display_write(display_dev, 0, x, y, &buf_desc, buf);
			if (ret) {
				LOG_ERR("cdc200_display_write failed (TOP_RIGHT)");
			}

			fill_buffer_fnc(BOTTOM_RIGHT, 0, buf, buf_size);
			x = capabilities.layer[0].x_resolution - rect_w;
			y = capabilities.layer[0].y_resolution - rect_h;

			ret = cdc200_display_write(display_dev, 0, x, y, &buf_desc, buf);
			if (ret) {
				LOG_ERR("cdc200_display_write failed (BOTTOM_RIGHT)");
			}

			sys_cache_data_flush_range((void *)fb_l2.fb_addr, fb_l2.fb_size);

			display_blanking_off(display_dev);

			k_msleep(10000);
		}

#if defined(CONFIG_MIPI_DSI)
		/* Return to command mode before DISPOFF, with the CDC still running. */
		dsi_dw_set_mode(dsi_dev, DSI_DW_COMMAND_MODE);
		display_blanking_on(panel_dev);
#endif /* defined(CONFIG_MIPI_DSI) */
		cdc200_set_enable(display_dev, false);
		display_blanking_on(display_dev);

		/* Release PM state locks after streaming is fully done */
		if (pm_locks_held) {
			pm_policy_state_lock_put(PM_STATE_SOFT_OFF, PM_ALL_SUBSTATES);
			pm_policy_state_lock_put(PM_STATE_SUSPEND_TO_RAM, PM_ALL_SUBSTATES);
			pm_locks_held = false;
		}

		/* Wait for hardware to fully reset */
		k_msleep(100);

		streaming_active = false;

		LOG_INF("Display: streaming cycle complete, waiting for next PM cycle");

		/* Signal main thread that streaming cycle is done */
		k_sem_give(&display_streaming_done_sem);

		/* Wait for next PM suspend/resume cycle instead of free-running.
		 * Without this, the thread starts unsolicited streaming without
		 * PM lock protection, which can corrupt hardware state if the
		 * system enters deep sleep mid-streaming.
		 */
		THREAD_TO_BE_SUSPEND = 1;
	}
}

int display_pm_thread_init(void)
{
	k_tid_t tid = k_thread_create(&thread_display, DisplayT_stack, STACKSIZE,
			&display_streaming_thread, NULL, NULL, NULL,
			DISPLAY_PRIORITY, 0, K_FOREVER);
	if (tid == NULL) {
		LOG_ERR("Error creating Display Thread");
		return -1;
	}

	return 0;
}

int display_pm_thread_start(void)
{
	/* Stay suspended until main explicitly resumes after the first PM cycle. */
	THREAD_TO_BE_SUSPEND = 1;
	THREAD_SUSPENDED = 0;

	k_thread_start(&thread_display);
	return 0;
}

int display_pm_thread_suspend(void)
{
	int ret;

	if (THREAD_SUSPENDED) {
		return 0;
	}

	was_streaming = streaming_active;
	THREAD_TO_BE_SUSPEND = 1;

	/* Wait for thread to acknowledge suspend request */
	ret = k_sem_take(&display_pm_suspended_sem, K_FOREVER);
	if (ret) {
		LOG_ERR("Display thread did not acknowledge suspend (err: %d)", ret);
		return ret;
	}

	LOG_INF("Display thread is now suspended (polling for resume)");

	/* The PM framework suspends the video devices as part of the system
	 * state transition, so nothing else is needed here.
	 */
	return 0;
}

int display_pm_thread_resume(void)
{
	LOG_INF("Display: Try to Resume...");

	/* Reset stale signal from interrupted capture cycles */
	k_sem_reset(&display_streaming_done_sem);

	/* Clear the suspend flag and signal semaphore to wake thread */
	THREAD_TO_BE_SUSPEND = 0;
	k_sem_give(&display_pm_resume_sem);

	LOG_INF("Display: resume signal sent");
	return 0;
}

int display_pm_thread_stop(void)
{
	int ret;

	LOG_INF("Display: requesting thread stop");

	THREAD_TO_BE_STOPPED = 1;

	/* Also clear suspend flag in case thread is currently suspended */
	THREAD_TO_BE_SUSPEND = 0;

	/* Wake thread if blocked on resume semaphore so it can check stop flag */
	k_sem_give(&display_pm_resume_sem);

	/* Wait for thread to finish */
	ret = k_thread_join(&thread_display, K_SECONDS(5));
	if (ret != 0) {
		LOG_ERR("Display thread join failed or timed out (err: %d)", ret);
		return ret;
	}

	LOG_INF("Display: thread stopped");
	return 0;
}

int display_pm_wait_streaming_done(void)
{
	return k_sem_take(&display_streaming_done_sem, K_FOREVER);
}

/**
 * Set the early init configuration for this application.
 */
static int app_board_early_init(void)
{
#if (defined(CONFIG_ENSEMBLE_GEN2) && defined(CONFIG_MIPI_DSI))
	const struct gpio_dt_spec cam_disp_mux_gpio =
		GPIO_DT_SPEC_GET(DT_NODELABEL(mipi_dsi), cam_disp_mux_gpios);
	gpio_pin_configure_dt(&cam_disp_mux_gpio, GPIO_OUTPUT_ACTIVE);
#endif

	return 0;
}
/*
 * CRITICAL: Must run at PRE_KERNEL_1 to restore SYSTOP before peripherals initialize.
 *
 * Priority 46 ensures this runs:
 *   - AFTER SE Services (priority 45) - SE must be ready for set_run_cfg()
 *   - BEFORE Power Domain (priority 47) - Power domain needs SYSTOP enabled
 *   - BEFORE UART and peripherals (priority 50+) - Peripherals need SYSTOP ON
 *
 * On cold boot: SYSTOP is already ON by default, safe to call.
 * On SOFT_OFF wakeup: SYSTOP is OFF, must restore BEFORE peripherals access registers.
 */
SYS_INIT(app_board_early_init, PRE_KERNEL_1, 46);
```

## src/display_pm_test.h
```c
/* Copyright (C) 2026 Alif Semiconductor - All Rights Reserved.
 * Use, distribution and modification of this code is permitted under the
 * terms stated in the Alif Semiconductor Software License Agreement
 *
 * You should have received a copy of the Alif Semiconductor Software
 * License Agreement with this file. If not, please write to:
 * contact@alifsemi.com, or visit: https://alifsemi.com/license
 *
 */

#ifndef __DISPLAY_PM_TEST_H__
#define __DISPLAY_PM_TEST_H__

int display_pm_thread_init(void);
int display_pm_thread_start(void);
int display_pm_thread_suspend(void);
int display_pm_thread_resume(void);
int display_pm_thread_stop(void);
int display_pm_wait_streaming_done(void);

#endif /* __DISPLAY_PM_TEST_H__ */
```
